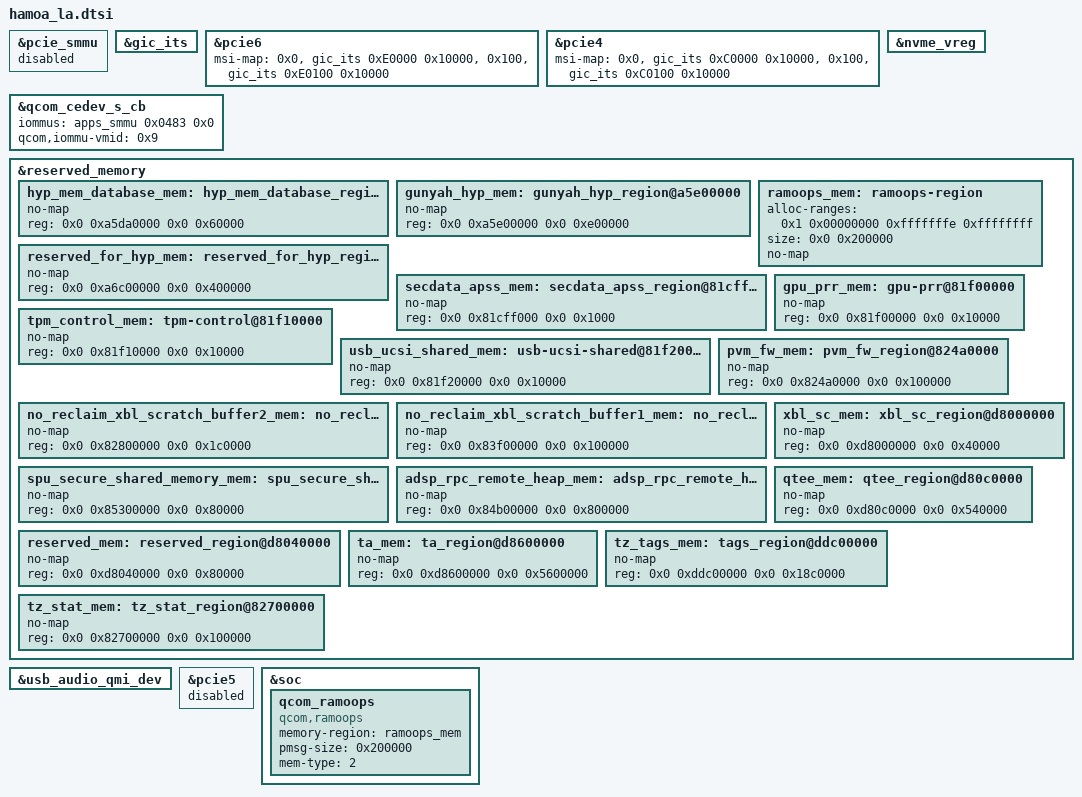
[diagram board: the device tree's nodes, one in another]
// SPDX-License-Identifier: BSD-3-Clause
/*
 * Copyright (c) Qualcomm Technologies, Inc. and/or its subsidiaries.
 */

#include "x1e80100.dtsi"

&pcie_smmu {
	status = "disabled";
};

&gic_its {
	status ="okay";
};

&pcie6 {
	msi-map = <0x0 &gic_its 0xE0000 0x10000>,
		  <0x100 &gic_its 0xE0100 0x10000>; /* 32 event IDs */

	/delete-property/ iommu-map;
};

&pcie4 {
	msi-map = <0x0 &gic_its 0xC0000 0x10000>,
		  <0x100 &gic_its 0xC0100 0x10000>; /* 32 event IDs */

	/delete-property/ iommu-map;
};

&nvme_vreg {
	/delete-property/ regulator-boot-on;
};

&qcom_cedev_s_cb {
	iommus = <&apps_smmu 0x0483 0x0>;
	qcom,iommu-vmid = <0x9>;
};


/delete-node/ &depthcharge_log_mem;
/delete-node/ &adsp_rpc_remote_heap_mem;
/delete-node/ &fdt_mem;
/delete-node/ &hyp_ac_config_mem;
/delete-node/ &qtee_mem;
/delete-node/ &ta_mem;
/delete-node/ &tfa_mem;
/delete-node/ &tz_ac_config_mem;
/delete-node/ &tz_stat_mem;
/delete-node/ &reserved_mem;

&reserved_memory {

	hyp_mem_database_mem: hyp_mem_database_region@a5da0000 {
		no-map;
		reg = <0x0 0xa5da0000 0x0 0x60000>;
	};

	gunyah_hyp_mem: gunyah_hyp_region@a5e00000 {
		no-map;
		reg = <0x0 0xa5e00000 0x0 0xe00000>;
	};

	reserved_for_hyp_mem: reserved_for_hyp_region@a6c00000 {
		no-map;
		reg = <0x0 0xa6c00000 0x0 0x400000>;
	};

	ramoops_mem: ramoops-region {
		alloc-ranges = <0x1 0x00000000 0xfffffffe 0xffffffff>;
		size = <0x0 0x200000>;
		no-map;
	};

	secdata_apss_mem: secdata_apss_region@81cff000 {
		no-map;
		reg = <0x0 0x81cff000 0x0 0x1000>;
	};

	gpu_prr_mem: gpu-prr@81f00000 {
		no-map;
		reg = <0x0 0x81f00000 0x0 0x10000>;
	};

	tpm_control_mem: tpm-control@81f10000 {
		no-map;
		reg = <0x0 0x81f10000 0x0 0x10000>;
	};

	usb_ucsi_shared_mem: usb-ucsi-shared@81f20000 {
		no-map;
		reg = <0x0 0x81f20000 0x0 0x10000>;
	};

	pvm_fw_mem: pvm_fw_region@824a0000 {
		no-map;
		reg = <0x0 0x824a0000 0x0 0x100000>;
	};

	no_reclaim_xbl_scratch_buffer2_mem: no_reclaim_xbl_scratch_buffer2_region@82800000 {
		no-map;
		reg = <0x0 0x82800000 0x0 0x1c0000>;
	};

	no_reclaim_xbl_scratch_buffer1_mem: no_reclaim_xbl_scratch_buffer1_region@83f00000 {
		no-map;
		reg = <0x0 0x83f00000 0x0 0x100000>;
	};

	spu_secure_shared_memory_mem: spu_secure_shared_memory_region@85300000 {
		no-map;
		reg = <0x0 0x85300000 0x0 0x80000>;
	};

	adsp_rpc_remote_heap_mem: adsp_rpc_remote_heap_region@84b00000 {
		no-map;
		reg = <0x0 0x84b00000 0x0 0x800000>;
	};

	xbl_sc_mem: xbl_sc_region@d8000000 {
		no-map;
		reg = <0x0 0xd8000000 0x0 0x40000>;
	};

	qtee_mem: qtee_region@d80c0000 {
		no-map;
		reg = <0x0 0xd80c0000 0x0 0x540000>;
	};

	reserved_mem: reserved_region@d8040000 {
		no-map;
		reg = <0x0 0xd8040000 0x0 0x80000>;
	};

	ta_mem: ta_region@d8600000 {
		no-map;
		reg = <0x0 0xd8600000 0x0 0x5600000>;
	};

	tz_tags_mem: tags_region@ddc00000 {
		no-map;
		reg = <0x0 0xddc00000 0x0 0x18c0000>;
	};

	tz_stat_mem: tz_stat_region@82700000 {
		no-map;
		reg = <0x0 0x82700000 0x0 0x100000>;
	};
};

&usb_audio_qmi_dev {
	status = "okay";
};

&pcie5 {
	status = "disabled";
};

&soc {
	qcom_ramoops {
		compatible = "qcom,ramoops";
		memory-region = <&ramoops_mem>;
		pmsg-size = <0x200000>;
		mem-type = <2>;
	};
};
